# CC2538NF53 register map
File version: 1.0
CPU: CM3 1.0, other endian, MPU, FPU, 3 interrupt priority bits
Registers are 32-bit, read-write, reset 0x0 unless marked. A register's access mark holds for its fields unless they carry their own. Offsets are from the block's base; [hi:lo] are bit positions.

## RFCORE_SFR — Register fields should be considered static unless otherwise noted as dynamic.
Base 0x40088800
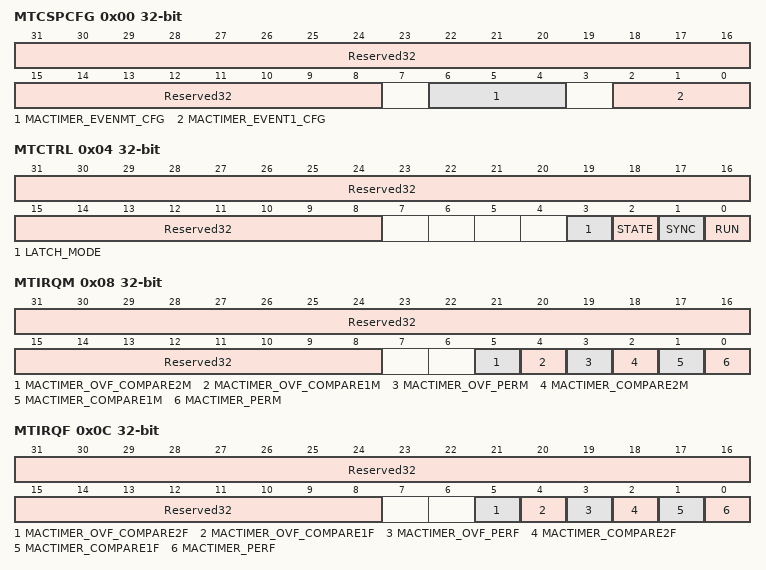
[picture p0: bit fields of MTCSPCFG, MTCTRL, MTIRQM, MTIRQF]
0x00 MTCSPCFG — MAC Timer event configuration
  [31:8] Reserved32 — [31:8] This register is 8 bits in a 32-bit address space.
  [6:4] MACTIMER_EVENMT_CFG — [6:4] Selects the event that triggers an MT_EVENT2 pulse 000: MT_per_event 001: MT_cmp1_event 010: MT_cmp2_event 011: MTovf_per_event 100: MTovf_cmp1_event 101: MTovf_cmp2_event 110: Reserved 111: No event
  [2:0] MACTIMER_EVENT1_CFG — [2:0] Selects the event that triggers an MT_EVENT1 pulse 000: MT_per_event 001: MT_cmp1_event 010: MT_cmp2_event 011: MTovf_per_event 100: MTovf_cmp1_event 101: MTovf_cmp2_event 110: Reserved 111: No event
0x04 MTCTRL — MAC Timer control register
  [31:8] Reserved32 — [31:8] This register is 8 bits in a 32-bit address space.
  [3] LATCH_MODE — [3:3] 0: Reading MTM0 with MTMSEL.MTMSEL = 000 latches the high byte of the timer, making it ready to be read from MTM1. Reading MTMOVF0 with MTMSEL.MTMOVFSEL = 000 latches the two most-significant bytes of the overflow counter, making it possible to read these from MTMOVF1 and MTMOVF2. 1: Reading MTM0 with MTMSEL.MTMSEL = 000 latches the high byte of the timer and the entire overflow counter at once, making it possible to read the values from MTM1, MTMOVF0, MTMOVF1, and MTMOVF2.
  [2] STATE — [2:2] State of MAC Timer 0: Timer idle 1: Timer running
  [1] SYNC — [1:1] 0: Starting and stopping of timer is immediate; that is, synchronous with clk_rf_32m. 1: Starting and stopping of timer occurs at the first positive edge of the 32-kHz clock. For more details regarding timer start and stop, see Section 22.4.
  [0] RUN — [0:0] Write 1 to start timer, write 0 to stop timer. When read, it returns the last written value.
0x08 MTIRQM — MAC Timer interrupt mask
  [31:8] Reserved32 — [31:8] This register is 8 bits in a 32-bit address space.
  [5] MACTIMER_OVF_COMPARE2M — [5:5] Enables the MACTIMER_OVF_COMPARE2 interrupt
  [4] MACTIMER_OVF_COMPARE1M — [4:4] Enables the MACTIMER_OVF_COMPARE1 interrupt
  [3] MACTIMER_OVF_PERM — [3:3] Enables the MACTIMER_OVF_PER interrupt
  [2] MACTIMER_COMPARE2M — [2:2] Enables the MACTIMER_COMPARE2 interrupt
  [1] MACTIMER_COMPARE1M — [1:1] Enables the MACTIMER_COMPARE1 interrupt
  [0] MACTIMER_PERM — [0:0] Enables the MACTIMER_PER interrupt
0x0C MTIRQF — MAC Timer interrupt flags
  [31:8] Reserved32 — [31:8] This register is 8 bits in a 32-bit address space.
  [5] MACTIMER_OVF_COMPARE2F — [5:5] Set when the MAC Timer overflow counter counts to the value set at MTovf_cmp2
  [4] MACTIMER_OVF_COMPARE1F — [4:4] Set when the MAC Timer overflow counter counts to the value set at Timer 2 MTovf_cmp1
  [3] MACTIMER_OVF_PERF — [3:3] Set when the MAC Timer overflow counter would have counted to a value equal to MTovf_per, but instead wraps to 0
  [2] MACTIMER_COMPARE2F — [2:2] Set when the MAC Timer counter counts to the value set at MT_cmp2
  [1] MACTIMER_COMPARE1F — [1:1] Set when the MAC Timer counter counts to the value set at MT_cmp1
  [0] MACTIMER_PERF — [0:0] Set when the MAC Timer counter would have counted to a value equal to MT_per, but instead wraps to 0
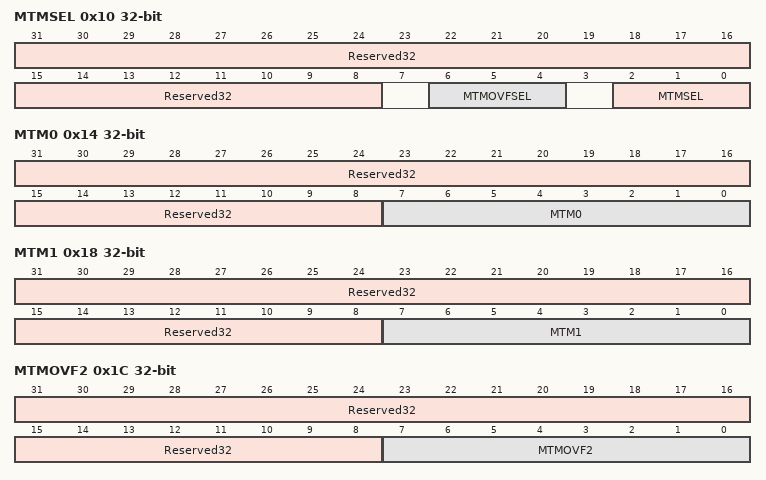
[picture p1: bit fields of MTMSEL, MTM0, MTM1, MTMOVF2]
0x10 MTMSEL — MAC Timer multiplex select
  [31:8] Reserved32 — [31:8] This register is 8 bits in a 32-bit address space.
  [6:4] MTMOVFSEL — [6:4] The value of this register selects the internal registers that are modified or read when accessing MTMOVF0, MTMOVF1, and MTMOVF2. 000: MTovf (overflow counter) 001: MTovf_cap (overflow capture) 010: MTovf_per (overflow period) 011: MTovf_cmp1 (overflow compare 1) 100: MTovf_cmp2 (overflow compare 2) 101 to 111: Reserved
  [2:0] MTMSEL — [2:0] The value of this register selects the internal registers that are modified or read when accessing MTM0 and MTM1. 000: MTtim (timer count value) 001: MT_cap (timer capture) 010: MT_per (timer period) 011: MT_cmp1 (timer compare 1) 100: MT_cmp2 (timer compare 2) 101 to 111: Reserved MTM0
0x14 MTM0 — MAC Timer multiplexed register 0
  [31:8] Reserved32 — [31:8] This register is 8 bits in a 32-bit address space.
  [7:0] MTM0 — [7:0] Indirectly returns and modifies bits [7:0] of an internal register depending on the value of MTMSEL.MTMSEL. When reading the MTM0 register with MTMSEL.MTMSEL set to 000 and MTCTRL.LATCH_MODE set to 0, the timer (MTtim) value is latched. When reading the MTM0 register with MTMSEL.MTMSEL set to 000 and MTCTRL.LATCH_MODE set to 1, the timer (MTtim) and overflow counter (MTovf) values are latched.
0x18 MTM1 — MAC Timer multiplexed register 1
  [31:8] Reserved32 — [31:8] This register is 8 bits in a 32-bit address space.
  [7:0] MTM1 — [7:0] Indirectly returns and modifies bits [15:8] of an internal register, depending on the value of MTMSEL.MTMSEL. When reading the MTM0 register with MTMSEL.MTMSEL set to 000, the timer (MTtim) value is latched. Reading this register with MTMSEL.MTMSEL set to 000 returns the latched value of MTtim[15:8].
0x1C MTMOVF2 — MAC Timer multiplexed overflow register 2
  [31:8] Reserved32 — [31:8] This register is 8 bits in a 32-bit address space.
  [7:0] MTMOVF2 — [7:0] Indirectly returns and modifies bits [23:16] of an internal register, depending on the value of MTMSEL.MTMOVFSEL. Reading this register with MTMSEL.MTMOVFSEL set to 000 returns the latched value of MTovf[23:16].
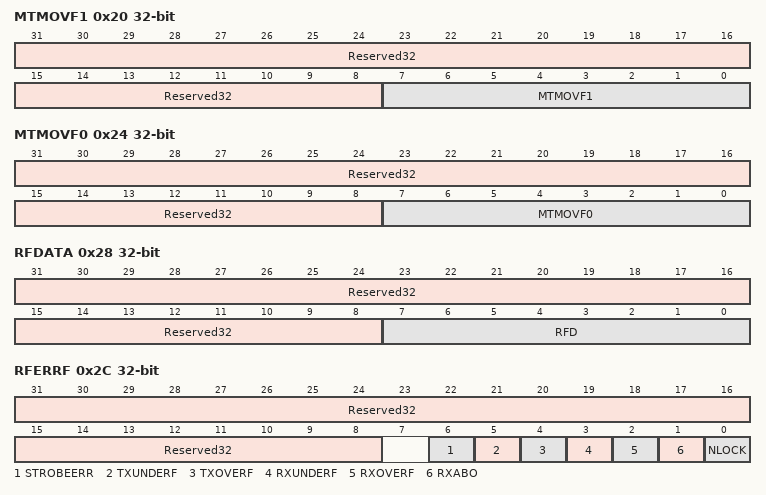
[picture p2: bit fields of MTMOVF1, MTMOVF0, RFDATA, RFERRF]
0x20 MTMOVF1 — MAC Timer multiplexed overflow register 1
  [31:8] Reserved32 — [31:8] This register is 8 bits in a 32-bit address space.
  [7:0] MTMOVF1 — [7:0] Indirectly returns and modifies bits [15:8] of an internal register, depending on the value of MTMSEL.MTMSEL. Reading this register with MTMSEL.MTMOVFSEL set to 000 returns the latched value of MTovf[15:8].
0x24 MTMOVF0 — MAC Timer multiplexed overflow register 0
  [31:8] Reserved32 — [31:8] This register is 8 bits in a 32-bit address space.
  [7:0] MTMOVF0 — [7:0] Indirectly returns and modifies bits [7:0] of an internal register, depending on the value of MTMSEL.MTMOVFSEL. When reading the MTMOVF0 register with MTMSEL.MTMOVFSEL set to 000 and MTCTRL.LATCH_MODE set to 0, the overflow counter value (MTovf) is latched. When reading the MTM0 register with MTMSEL.MTMOVFSEL set to 000 and MTCTRL.LATCH_MODE set to 1, the overflow counter value (MTovf) is latched.
0x28 RFDATA — The TX FIFO and RX FIFO may be accessed through this register. Data is written to the TX FIFO when writing to the RFD register. Data is read from the RX FIFO when the RFD register is read. The XREG registers RXFIFOCNT and TXFIFOCNT provide information on the amount of data in the FIFOs. The FIFO contents can be cleared by issuing SFLUSHRX and SFLUSHTX.
  [31:8] Reserved32 — [31:8] This register is 8 bits in a 32-bit address space.
  [7:0] RFD — [7:0] Data written to the register is written to the TX FIFO. When reading this register, data from the RX FIFO is read.
0x2C RFERRF — RF error interrupt flags
  [31:8] Reserved32 — [31:8] This register is 8 bits in a 32-bit address space.
  [6] STROBEERR — [6:6] A command strobe was issued when it could not be processed. Triggered if trying to disable the radio when it is already disabled, or when trying to do a SACK, SACKPEND, or SNACK command when not in active RX. 0: No interrupt pending 1: Interrupt pending
  [5] TXUNDERF — [5:5] TX FIFO underflowed. 0: No interrupt pending 1: Interrupt pending
  [4] TXOVERF — [4:4] TX FIFO overflowed. 0: No interrupt pending 1: Interrupt pending
  [3] RXUNDERF — [3:3] RX FIFO underflowed. 0: No interrupt pending 1: Interrupt pending
  [2] RXOVERF — [2:2] RX FIFO overflowed. 0: No interrupt pending 1: Interrupt pending
  [1] RXABO — [1:1] Reception of a frame was aborted. 0: No interrupt pending 1: Interrupt pending
  [0] NLOCK — [0:0] The frequency synthesizer failed to achieve lock after time-out, or lock is lost during reception. The receiver must be restarted to clear this error situation. 0: No interrupt pending 1: Interrupt pending
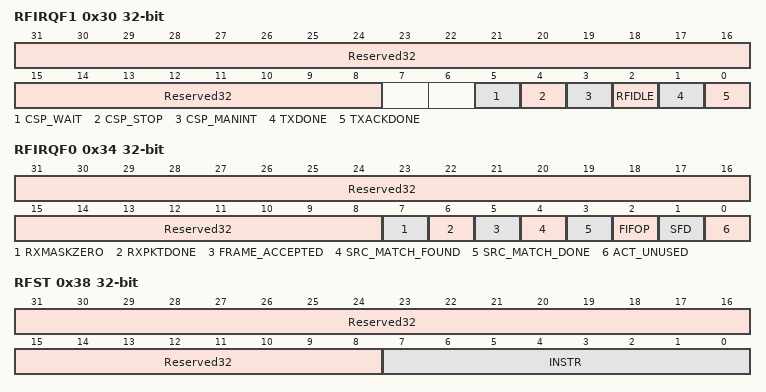
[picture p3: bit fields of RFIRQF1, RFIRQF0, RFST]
0x30 RFIRQF1 — RF interrupt flags
  [31:8] Reserved32 — [31:8] This register is 8 bits in a 32-bit address space.
  [5] CSP_WAIT — [5:5] Execution continued after a wait instruction in CSP. 0: No interrupt pending 1: Interrupt pending
  [4] CSP_STOP — [4:4] CSP has stopped program execution. 0: No interrupt pending 1: Interrupt pending
  [3] CSP_MANINT — [3:3] Manual interrupt generated from CSP 0: No interrupt pending 1: Interrupt pending
  [2] RFIDLE — [2:2] Radio state-machine has entered the IDLE state. 0: No interrupt pending 1: Interrupt pending
  [1] TXDONE — [1:1] A complete frame has been transmitted. 0: No interrupt pending 1: Interrupt pending
  [0] TXACKDONE — [0:0] An acknowledgement frame has been completely transmitted. 0: No interrupt pending 1: Interrupt pending
0x34 RFIRQF0 — RF interrupt flags
  [31:8] Reserved32 — [31:8] This register is 8 bits in a 32-bit address space.
  [7] RXMASKZERO — [7:7] The RXENABLE register has gone from a nonzero state to an all-zero state. 0: No interrupt pending 1: Interrupt pending
  [6] RXPKTDONE — [6:6] A complete frame has been received. 0: No interrupt pending 1: Interrupt pending
  [5] FRAME_ACCEPTED — [5:5] Frame has passed frame filtering. 0: No interrupt pending 1: Interrupt pending
  [4] SRC_MATCH_FOUND — [4:4] Source match is found. 0: No interrupt pending 1: Interrupt pending
  [3] SRC_MATCH_DONE — [3:3] Source matching is complete. 0: No interrupt pending 1: Interrupt pending
  [2] FIFOP — [2:2] The number of bytes in the RX FIFO is greater than the threshold. Also raised when a complete frame is received, and when a packet is read out completely and more complete packets are available. 0: No interrupt pending 1: Interrupt pending
  [1] SFD — [1:1] SFD has been received or transmitted. 0: No interrupt pending 1: Interrupt pending
  [0] ACT_UNUSED — [0:0] Reserved 0: No interrupt pending 1: Interrupt pending
0x38 RFST — RF CSMA-CA/strobe processor
  [31:8] Reserved32 — [31:8] This register is 8 bits in a 32-bit address space.
  [7:0] INSTR — [7:0] Data written to this register is written to the CSP instruction memory. Reading this register returns the CSP instruction currently being executed.
